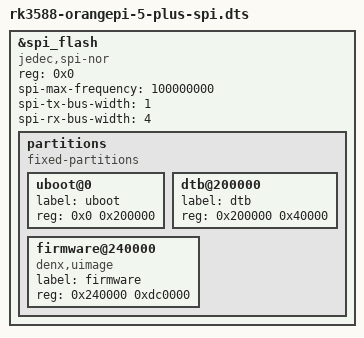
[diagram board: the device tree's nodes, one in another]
// SPDX-License-Identifier: (GPL-2.0+ OR MIT)
/*
 * Copyright (c) 2021 Rockchip Electronics Co., Ltd.
 *
 */

/dts-v1/;

#include "rk3588-orangepi-5-plus.dts"

&spi_flash {
	#address-cells = <1>;
	#size-cells = <0>;
	compatible = "jedec,spi-nor";
	reg = <0x0>;
	spi-max-frequency = <100000000>;
	spi-tx-bus-width = <1>;
	spi-rx-bus-width = <4>;
	status = "okay";

	partitions {
		compatible = "fixed-partitions";
		#address-cells = <1>;
		#size-cells = <1>;

		uboot@0 {
			label = "uboot";
			reg = <0x0 0x200000>;
		};

		dtb@200000 {
			label = "dtb";
			reg = <0x200000 0x40000>;
		};

		firmware@240000 {
			compatible = "denx,uimage";
			label = "firmware";
			reg = <0x240000 0xdc0000>;
		};
	};
};
